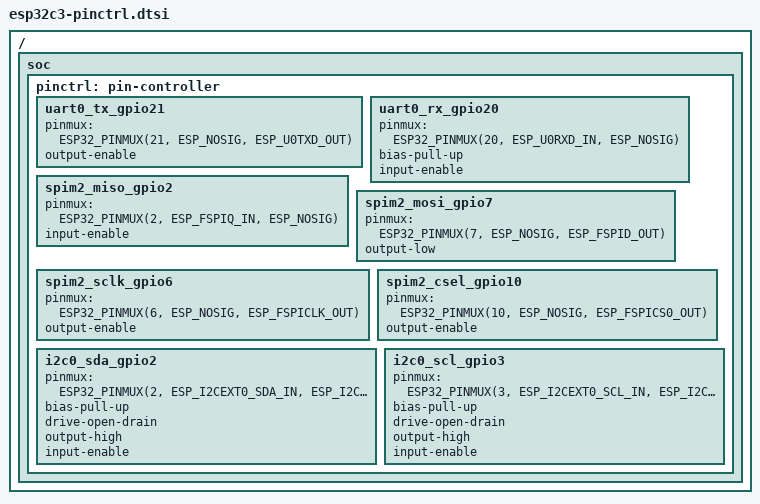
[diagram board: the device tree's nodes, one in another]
/*
 * TODO: this file must be autogenerated and
 * moved to hal/espressif
 *
 * SPDX-License-Identifier: Apache-2.0
 */

#include <dt-bindings/pinctrl/esp32-pinctrl.h>
#include <dt-bindings/pinctrl/esp32c3-gpio-sigmap.h>

/ {
	soc {
		pinctrl: pin-controller {

			/* UART_0 TX pin states */
			uart0_tx_gpio21: uart0_tx_gpio21 {
				pinmux = <ESP32_PINMUX(21, ESP_NOSIG, ESP_U0TXD_OUT)>;
				output-enable;
			};

			/* UART_0 RX pin states */
			uart0_rx_gpio20: uart0_rx_gpio20 {
				pinmux = <ESP32_PINMUX(20, ESP_U0RXD_IN, ESP_NOSIG)>;
				bias-pull-up;
				input-enable;
			};

			/* SPIM_2 MISO pin states */
			spim2_miso_gpio2: spim2_miso_gpio2 {
				pinmux = <ESP32_PINMUX(2, ESP_FSPIQ_IN, ESP_NOSIG)>;
				input-enable;
			};

			/* SPIM_2 MOSI pin states */
			spim2_mosi_gpio7: spim2_mosi_gpio7 {
				pinmux = <ESP32_PINMUX(7, ESP_NOSIG, ESP_FSPID_OUT)>;
				output-low;
			};

			/* SPIM_2 SCLK pin states */
			spim2_sclk_gpio6: spim2_sclk_gpio6 {
				pinmux = <ESP32_PINMUX(6, ESP_NOSIG, ESP_FSPICLK_OUT)>;
				output-enable;
			};

			/* SPIM_2 CSEL pin states */
			spim2_csel_gpio10: spim2_csel_gpio10 {
				pinmux = <ESP32_PINMUX(10, ESP_NOSIG, ESP_FSPICS0_OUT)>;
				output-enable;
			};

			/* I2C_0 SDA pin states */
			i2c0_sda_gpio2: i2c0_sda_gpio2 {
				pinmux = <ESP32_PINMUX(2, ESP_I2CEXT0_SDA_IN, ESP_I2CEXT0_SDA_OUT)>;
				bias-pull-up;
				drive-open-drain;
				output-high;
				input-enable;
			};

			/* I2C_0 SCL pin states */
			i2c0_scl_gpio3: i2c0_scl_gpio3 {
				pinmux = <ESP32_PINMUX(3, ESP_I2CEXT0_SCL_IN, ESP_I2CEXT0_SCL_OUT)>;
				bias-pull-up;
				drive-open-drain;
				output-high;
				input-enable;
			};

		};
	};
};
